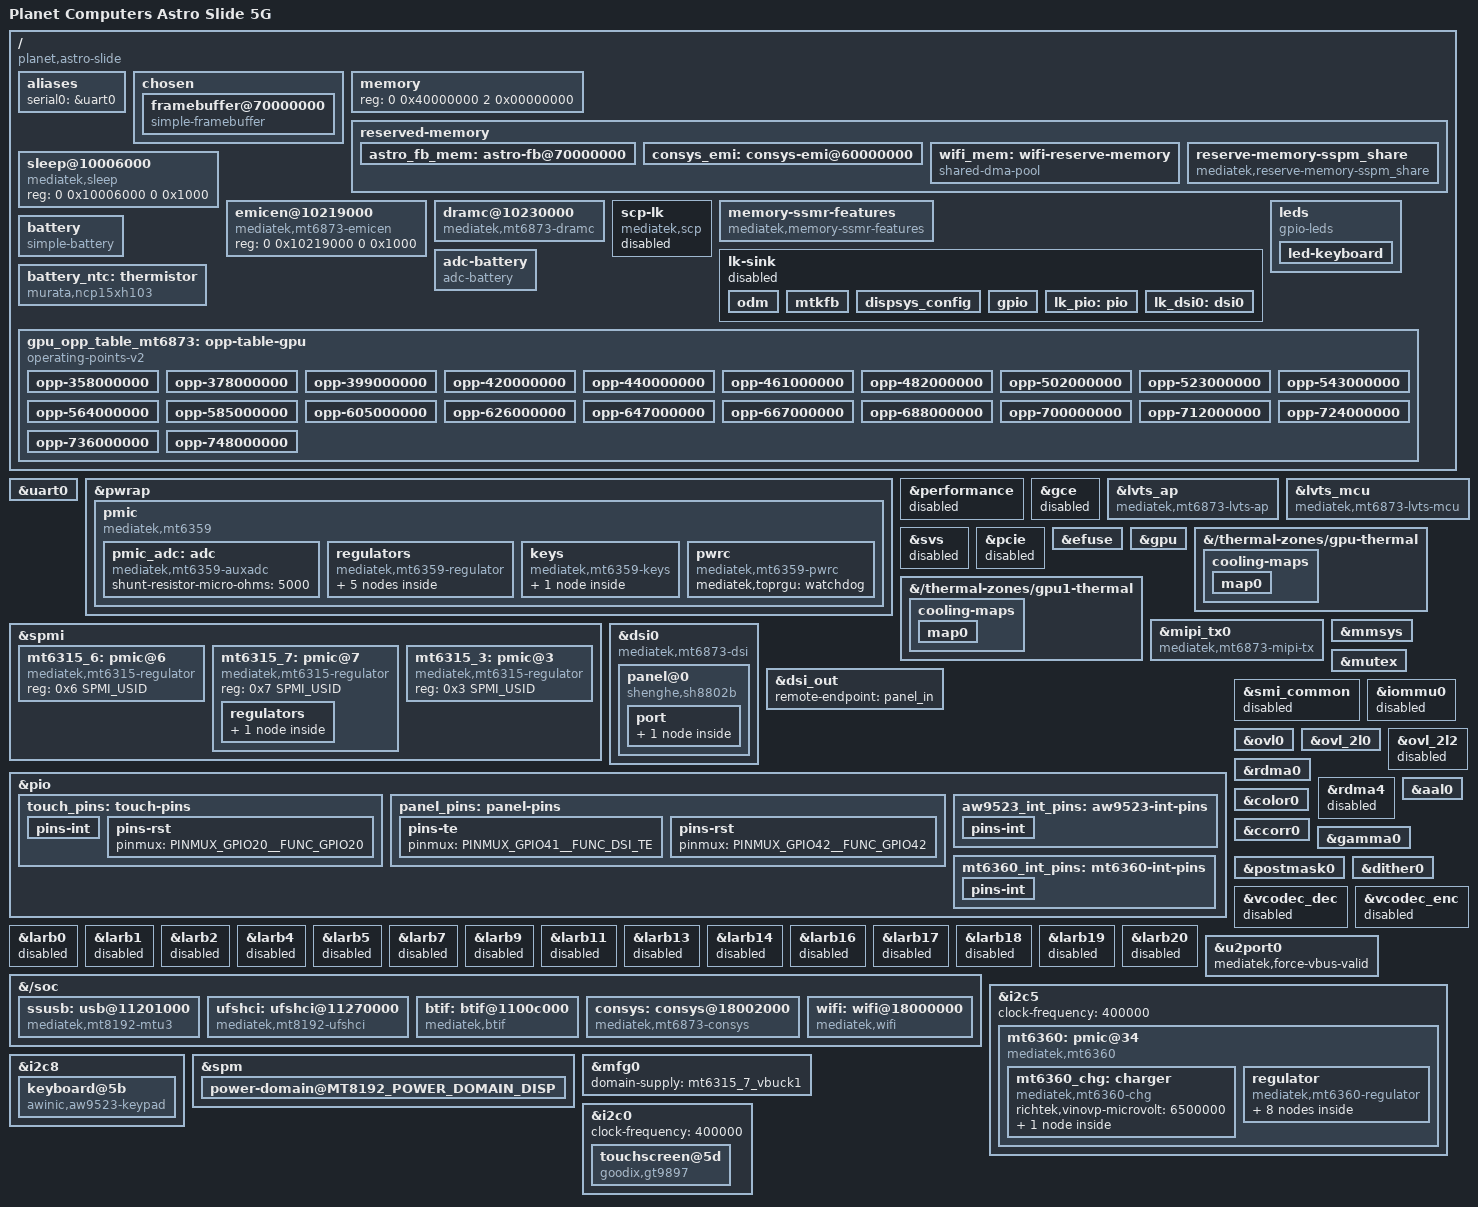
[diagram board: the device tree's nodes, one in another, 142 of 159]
// SPDX-License-Identifier: GPL-2.0-only
/*
 * Planet Computers Astro Slide 5G (MediaTek MT6873 / Dimensity 800)
 *
 * Phase P1 "escape test" skeleton: CPUs, GIC, timers, watchdog, UART0,
 * LK's framebuffer (simpledrm) and the keyboard backlight as a heartbeat.
 * Built on mt8192.dtsi: the MT6873 shares the MT8192 register map (97/102
 * mt8192.dtsi addressed nodes at identical addresses) and pin table (228
 * pins, identical mux functions). Receipts: docs/hardware-map.md.
 *
 * Board facts are from Planet's 4.14.186 BSP (astro-kernel a79860700:
 * arch/arm64/boot/dts/mediatek/mt6873.dts + aeon_gpio.dtsi) and from the
 * stock images dumped 2026-11-25 (docs/p0-findings.md).
 *
 * Deliberately NOT enabled (AGENTS.md rules 3 and 5):
 *  - pwrap / MT6359P / mt6359-keys: nothing in Linux may touch the PMIC
 *    until the power-key reset path is understood (STRUP_CON12 vs the
 *    TOP_RST_MISC register mainline mtk-pmic-keys writes).
 *  - Display pipeline (mmsys, OVL, RDMA, DSI, M4U): LK owns the SH8802B
 *    command-mode panel; Linux only reads its registers (initramfs).
 *  - SPMI/MT6315, SCP, GPU, everything else (USB: device port only;
 *    UFS without its VCC regulator; i2c8 for the keyboard only: below).
 *
 * LK contract (same LK family as the Cosmo, lk_a strings):
 *  - LK applies `dtbo` to this DTB and refuses to boot if that fails:
 *    build with -@ and flash the no-op overlay (dtbo/astro-noop.dts).
 *  - LK needs /chosen/bootargs (bootargs.c fdt_bootargs) and rewrites
 *    the node at the exact path /memory ("ERROR: /memory node not exist,
 *    while(1)").
 *  - LK adds its own mblock-N-<name> no-map carve-outs to /reserved-memory
 *    (ATF, TEE, SSPM, SPM, SCP, modem, framebuffer, ram_console, pstore):
 *    none of them is declared here (a duplicate hung the Gemini), but the
 *    container must exist, with the vendor nodes LK's fixups look up
 *    (below the memory node).
 */

/dts-v1/;
#include <dt-bindings/gpio/gpio.h>
#include <dt-bindings/spmi/spmi.h>
#include <dt-bindings/iio/adc/mediatek,mt6359-auxadc.h>
#include <dt-bindings/input/input.h>
#include <dt-bindings/interrupt-controller/irq.h>
#include <dt-bindings/leds/common.h>
#include <dt-bindings/phy/phy.h>
#include "mt8192.dtsi"

/ {
	model = "Planet Computers Astro Slide 5G";
	chassis-type = "handset";
	compatible = "planet,astro-slide", "mediatek,mt6873",
		     "mediatek,mt8192";

	aliases {
		serial0 = &uart0;
	};

	chosen {
		#address-cells = <2>;
		#size-cells = <2>;
		ranges;

		/* vendor: console=ttyS0,921600n1; no UART pad is known yet */
		stdout-path = "serial0:921600n8";

		/*
		 * LK builds the kernel cmdline on top of this property and
		 * asserts without it (Cosmo LK log 2026-10-25; the Astro LK
		 * carries the same app/mt_boot/bootargs.c fdt_bootargs).
		 * The boot.img header cmdline adds the rest.
		 */
		bootargs = "console=tty0 console=ttyS0,921600n1";

		/*
		 * Console framebuffer: our own buffer (astro_fb_mem below), not
		 * LK's. LK's framebuffer (0x7dd80000, OVL0_2L layer 0) sits in a
		 * mapped mblock (map:1): arm64 refuses ioremap/WC of mapped RAM
		 * (simpledrm -12, usb2 dmesg), and a second reservation over an LK
		 * mblock made the Cosmo's LK refuse to boot. The display path is
		 * pointed at this buffer by /bin/astro-disp fb (OVL0_2L layer 0
		 * address), keeping LK's layer setup: 1080x2340, pitch 4352,
		 * eBGRA8888 (B,G,R,A in memory = a8r8g8b8, Cosmo-proven).
		 * The panel is command mode: nothing appears until astro-disp
		 * sends a frame.
		 */
		framebuffer@70000000 {
			compatible = "simple-framebuffer";
			reg = <0 0x70000000 0 0x9b6400>;
			width = <1080>;
			height = <2340>;
			stride = <4352>;
			format = "a8r8g8b8";
		};
	};

	/*
	 * 8 GiB at 0x40000000: DRAM rank0 0x100000000 + rank1 0x100000000
	 * (preloader log in expdb). Named "memory" (not memory@40000000):
	 * LK looks the node up by that exact path and rewrites it.
	 */
	memory {
		device_type = "memory";
		reg = <0 0x40000000 2 0x00000000>;
	};

	/*
	 * Vendor nodes LK's final fixup pass looks up in this DTB (try1b,
	 * 2026-11-25: each missing one logged an error that a stock boot does
	 * not log, then "ASSERT at (app/mt_boot/mt_boot.c:991)"). Copied from
	 * the stock base DTB (boot_a dtb section) minus phandle references to
	 * vendor nodes we do not carry. No mainline driver matches any of
	 * these compatibles.
	 *
	 * /reserved-memory: LK adds its mblock-N-<name> carve-outs here
	 * ("[DRAMC] Warning: can't find reserved-memory node") and resizes
	 * the SSPM pool by path ("SSPM: no reserved mem found, skip").
	 * Nothing LK reserves itself is declared (Gemini lesson).
	 */
	reserved-memory {
		#address-cells = <2>;
		#size-cells = <2>;
		ranges;

		/*
		 * Console framebuffer (chosen/framebuffer@70000000). Free RAM in
		 * LK's map (its mblock/reserve list, docs/p0-findings.md: nothing
		 * between 0x60000000 and 0x77ff0000). no-map so simpledrm's
		 * ioremap path works and the display engine reads uncached data.
		 */
		astro_fb_mem: astro-fb@70000000 {
			reg = <0 0x70000000 0 0xa00000>;
			no-map;
		};

		/*
		 * Wi-Fi W2: CONSYS EMI window (stock: 4 MiB, 16 MiB aligned,
		 * dynamic in 0x40000000-0xc0000000). Fixed here, in the free
		 * 0x60000000-0x77ff0000 gap of LK's map (p0-findings; checked
		 * again against every mblock LK logged, 2026-11-25), clear of
		 * LK's scratch (0x4e000000-0x56000000) and load areas.
		 */
		consys_emi: consys-emi@60000000 {
			reg = <0 0x60000000 0 0x400000>;
			no-map;
		};

		/* Wi-Fi DMA pool, as stock (gen4m reads "size") */
		wifi_mem: wifi-reserve-memory {
			compatible = "shared-dma-pool";
			no-map;
			size = <0 0x600000>;
			alignment = <0 0x1000000>;
			alloc-ranges = <0 0x40000000 0 0x80000000>;
		};

		reserve-memory-sspm_share {
			compatible = "mediatek,reserve-memory-sspm_share";
			no-map;
			status = "okay";
			size = <0 0x510000>;
			alignment = <0 0x10000>;
			alloc-ranges = <0 0x40000000 0 0x60000000>;
		};
	};

	/* LK records the SPM firmware here ("/sleep not found. LINE: 101") */
	sleep@10006000 {
		compatible = "mediatek,sleep";
		reg = <0 0x10006000 0 0x1000>;
	};

	/* "ERROR: EMI info incorrect" without it */
	emicen@10219000 {
		compatible = "mediatek,mt6873-emicen", "mediatek,common-emicen";
		reg = <0 0x10219000 0 0x1000>;
	};

	/* "[set_fdt_dramc] get_path_offset fail" / "DRAMC info incorrect" */
	dramc@10230000 {
		compatible = "mediatek,mt6873-dramc", "mediatek,common-dramc";
		reg = <0 0x10230000 0 0x2000>, <0 0x10240000 0 0x2000>,
		      <0 0x10234000 0 0x1000>, <0 0x10244000 0 0x1000>,
		      <0 0x10238000 0 0x2000>, <0 0x10248000 0 0x2000>,
		      <0 0x10236000 0 0x1000>, <0 0x10246000 0 0x1000>,
		      <0 0x10006000 0 0x1000>;
		mr4_version = <1>;
		mr4_rg = <0x90 0xffff 0>;
		fmeter_version = <1>;
		crystal_freq = <52>;
		pll_id = <0x50c 0x100 8>;
		shu_lv = <0x50c 0x30000 16>;
		shu_of = <0x700>;
		sdmpcw = <0x704 0xffff0000 16 0x724 0xffff0000 16>;
		prediv = <0x708 0xc0000 18 0x728 0xc0000 18>;
		posdiv = <0x708 7 0 0x728 7 0>;
		ckdiv4 = <0x874 4 2 0x874 4 2>;
		pll_md = <0x744 0x100 8 0x744 0x100 8>;
		cldiv2 = <0x8b4 2 1 0x8b4 2 1>;
		fbksel = <0x70c 0x40 6 0x70c 0x40 6>;
		dqsopen = <0x870 0x100000 20 0x870 0x100000 20>;
		dqopen = <0x870 0x200000 21 0x870 0x200000 21>;
	};

	/*
	 * LK sets the SCP core status here ("[SCP] platform_fdt_scp: getting
	 * node from dtb fails"). Only the properties LK reads; no reg, so it
	 * claims no MMIO. Mainline SCP stays off (CONFIG_MTK_SCP=n).
	 */
	scp-lk {
		compatible = "mediatek,scp";
		status = "disabled";
		core_0 = "enable";
		scp_sramSize = <0x100000>;
	};

	/*
	 * Secure-memory sizes LK's memory_ssmr_fixup reads (stock logs the
	 * scenarios, then "get ssmr-reserved-cma_memory failed" and goes on;
	 * no ssmr/zmc pool is declared, so it fails the same way here).
	 */
	memory-ssmr-features {
		compatible = "mediatek,memory-ssmr-features";
		svp-size = <0 0x10000000>;
		2d_fr-size = <0 0>;
		tui-size = <0 0x4000000>;
		prot-sharedmem-size = <0 0x8000000>;
		ta-elf-size = <0 0x1000000>;
		ta-stack-heap-size = <0 0x6000000>;
		sdsp-tee-sharedmem-size = <0 0x1000000>;
		sdsp-firmware-size = <0 0x1000000>;
	};

	/*
	 * Landing area for LK's second `dtbo` pass (display test 1,
	 * 2026-11-25). LK applies dtbo/astro-lk.dts to its own DTB, where it
	 * feeds LK's panel, backlight and GPIO setup, and then to this DTB,
	 * where a failure stops the boot. Its fragments target odm, pio,
	 * mtkfb, dispsys_config, dsi0 and gpio. Here those symbols all point
	 * into this node: bin/build-boot-img.sh rewrites __symbols__ pio and
	 * dsi0 (mainline labels of the real pinctrl and DSI nodes) to
	 * lk_pio / lk_dsi0. No compatible and disabled, so Linux never
	 * creates a device for anything the overlay puts here.
	 */
	lk-sink {
		status = "disabled";

		odm: odm {
		};

		mtkfb: mtkfb {
		};

		dispsys_config: dispsys_config {
		};

		gpio: gpio {
		};

		lk_pio: pio {
		};

		lk_dsi0: dsi0 {
		};
	};

	/*
	 * Heartbeat on the keyboard backlight, the only light Linux can
	 * drive without the PMIC: GPIO28, active high (vendor aeon_gpio.dtsi
	 * keyboardlight_gpio_low = GPIO28 output-low = off;
	 * aw9523_key.c drives it as PWM0 at 100 % for full on). Blinking =
	 * the kernel is alive; steady/off after a while = it is not.
	 */
	leds {
		compatible = "gpio-leds";

		led-keyboard {
			gpios = <&pio 28 GPIO_ACTIVE_HIGH>;
			function = LED_FUNCTION_KBD_BACKLIGHT;
			color = <LED_COLOR_ID_WHITE>;
			linux,default-trigger = "heartbeat";
			default-state = "off";
		};
	};

	/*
	 * Battery data from the stock DTB (bat_gm30, boot_a dumped
	 * 2026-11-25; identical to the vendor mt6873_battery_table.dtsi):
	 * battery0_profile_t0..t4 (50/25/10/0/-10 C, 100 rows of
	 * {0.1 mAh, 0.1 mV, 0.1 mOhm}) resampled to capacity percent of each
	 * table's own Qmax down to SHUTDOWN_GAUGE0_VOLTAGE 3.40 V; internal
	 * resistance = median of the 25 C resistance column (90 mOhm) +
	 * R_FG_VALUE 5 mOhm + FG_METER_RESISTANCE 10 mOhm, as stock's IR
	 * compensation adds them; temperature scaling = median per table. The charger runs CV 4.35 V (LK's
	 * setting, mt6360-chg); stock battery_cv is 4.40 V.
	 */
	battery: battery {
		compatible = "simple-battery";
		voltage-min-design-microvolt = <3400000>;
		constant-charge-voltage-max-microvolt = <4350000>;
		factory-internal-resistance-micro-ohms = <105000>;
		resistance-temp-table = <50 60>, <25 100>, <10 100>, <0 566>, <(-10) 1024>;
		ocv-capacity-celsius = <25 50 10 0 (-10)>;
		/* 25 C: Qmax 4593.7 mAh to 3.40 V, median R 90 mOhm */
		ocv-capacity-table-0 = <4378700 100>, <4311104 95>, <4245028 90>, <4180598 85>,
					<4118212 80>, <4059719 75>, <4000408 70>, <3955341 65>,
					<3892230 60>, <3850965 55>, <3822506 50>, <3799880 45>,
					<3782051 40>, <3761540 35>, <3738252 30>, <3727280 25>,
					<3698184 20>, <3681272 15>, <3679895 10>, <3670013 5>,
					<3633326 4>, <3589537 3>, <3506523 2>, <3452426 1>,
					<3400000 0>;
		/* 50 C: Qmax 4575.0 mAh to 3.40 V, median R 54 mOhm */
		ocv-capacity-table-1 = <4375000 100>, <4308978 95>, <4244512 90>, <4180937 85>,
					<4119412 80>, <4061913 75>, <4008866 70>, <3961885 65>,
					<3902399 60>, <3857622 55>, <3827781 50>, <3803997 45>,
					<3785460 40>, <3761608 35>, <3731165 30>, <3717634 25>,
					<3708163 20>, <3686832 15>, <3669182 10>, <3653091 5>,
					<3619440 4>, <3569195 3>, <3499717 2>, <3443580 1>,
					<3400000 0>;
		/* 10 C: Qmax 4593.7 mAh to 3.40 V, median R 90 mOhm */
		ocv-capacity-table-2 = <4378700 100>, <4311104 95>, <4245028 90>, <4180598 85>,
					<4118212 80>, <4059719 75>, <4000408 70>, <3955341 65>,
					<3892230 60>, <3850965 55>, <3822506 50>, <3799880 45>,
					<3782051 40>, <3761540 35>, <3738252 30>, <3713958 25>,
					<3693538 20>, <3680753 15>, <3679650 10>, <3670696 5>,
					<3647727 4>, <3602510 3>, <3550219 2>, <3494452 1>,
					<3400000 0>;
		/* 0 C: Qmax 4566.0 mAh to 3.40 V, median R 509 mOhm */
		ocv-capacity-table-3 = <4395400 100>, <4317019 95>, <4250195 90>, <4186618 85>,
					<4126582 80>, <4070805 75>, <3999152 70>, <3940020 65>,
					<3896736 60>, <3857790 55>, <3828199 50>, <3804765 45>,
					<3786148 40>, <3773212 35>, <3770481 30>, <3733814 25>,
					<3694252 20>, <3655631 15>, <3465239 10>, <3444633 5>,
					<3441220 4>, <3437912 3>, <3428367 2>, <3414184 1>,
					<3400000 0>;
		/* -10 C: Qmax 2745.1 mAh to 3.40 V, median R 922 mOhm */
		ocv-capacity-table-4 = <4390100 100>, <4331464 95>, <4284580 90>, <4241603 85>,
					<4200695 80>, <4162661 75>, <4124578 70>, <4086793 65>,
					<4054362 60>, <4006918 55>, <3962901 50>, <3931323 45>,
					<3909276 40>, <3886207 35>, <3863672 30>, <3843448 25>,
					<3825581 20>, <3810172 15>, <3797309 10>, <3786565 5>,
					<3784837 4>, <3781620 3>, <3711396 2>, <3551603 1>,
					<3400000 0>;
	};

	/*
	 * Battery NTC on the MT6359P BAT_TEMP pin. Stock (mtk_battery_table.h,
	 * BAT_NTC_10): 10 kOhm NTC to ground, RBAT_PULL_UP_R 24 kOhm to
	 * RBAT_PULL_UP_VOLT 2.8 V (VBIF28, reads 2.80 V), R = Rpu*V/(Vpu-V);
	 * Fg_Temperature_Table is the NCP15XH103 table value for value.
	 * BIF_NTC_R only applies to BIF batteries (none here).
	 */
	battery_ntc: thermistor {
		compatible = "murata,ncp15xh103";
		io-channels = <&pmic_adc MT6359_AUXADC_BAT_TEMP>;
		pullup-uv = <2800000>;
		pullup-ohm = <24000>;
		pulldown-ohm = <0>;
		#io-channel-cells = <0>;
	};

	/*
	 * Battery voltage and current from the MT6359P AUXADC impedance
	 * measurement (IMP: VBAT and the fuel gauge FG_R_CURR), temperature
	 * from the NTC; capacity by adc-battery-helper (OCV = V - I*R, R
	 * learnt from load steps, OCV table and initial R by temperature).
	 */
	adc-battery {
		compatible = "adc-battery";
		io-channels = <&pmic_adc MT6359_AUXADC_VBAT>,
			      <&pmic_adc MT6359_AUXADC_IBAT>,
			      <&battery_ntc>;
		io-channel-names = "voltage", "current", "temperature";
		monitored-battery = <&battery>;
		power-supplies = <&mt6360_chg>;
	};
};

&uart0 {
	status = "okay";
};

/*
 * pwrap: the only path to the MT6359P (AGENTS.md rule 5, docs/pmic-plan.md).
 * LK/ATF leave it initialised (PMIF INIT_DONE 0x1, WACS2_RDATA bit 15), so
 * mainline skips init; the clock parent is already osc_d10. Step 2 image B:
 * the PMIC core and the power key only; bin/build-boot-img.sh refuses any
 * other shape.
 *
 * MT6359P interrupt: pio EINT 214, level high (stock DTB).
 */
&pwrap {
	status = "okay";

	pmic: pmic {
		compatible = "mediatek,mt6359";
		interrupts-extended = <&pio 214 IRQ_TYPE_LEVEL_HIGH>;
		interrupt-controller;
		#interrupt-cells = <2>;

		/*
		 * Power key (TOPSTATUS bit 1). Reported as Esc, as on the
		 * Cosmo; "hold for power" is userspace policy. The long-press
		 * reset is stated as stock leaves it (STRUP_CON12 0x21e0:
		 * one key, 8 s; hal_kpd.c ONEKEY_REBOOT, LPRST_TD 0), so the
		 * driver (MT6359P delta) finds it set and writes nothing.
		 * No home key on the Astro.
		 */
		/*
		 * AUXADC (step 3A). Probe resets the AUXADC (HK_TOP_RST_CON0
		 * 0xf90 bits 0/3 under the 0xfb4 key); reads write the request
		 * registers (0x1108/0x110a) and IMP0 (0x1208). Nothing in STRUP.
		 * Sense resistor: stock R_FG_VALUE 5 mOhm, CAR_TUNE 100 (1.0).
		 */
		pmic_adc: adc {
			compatible = "mediatek,mt6359-auxadc";
			#io-channel-cells = <1>;
			shunt-resistor-micro-ohms = <5000>;
		};

		/*
		 * Wi-Fi W2 (docs/wifi-stock.md): only the five CONSYS rails, for
		 * the vendor mt6873.c consumer. Every other MT6359P regulator
		 * has no node, so the core gives it no constraints and never
		 * writes it (and regulator_ignore_unused is on the cmdline).
		 * No always-on/boot-on: nothing is enabled at registration.
		 * Ranges cover what LK leaves (VCN33 VOSEL 0xf = 3.5 V, VCN13
		 * 1.3 V, 2026-11-25 read-out) so registration writes nothing;
		 * mt6873.c sets 1.8/1.3/3.3 V itself when Wi-Fi powers on.
		 * Addresses (mainline mt6359p table = Planet registers.h):
		 * VCN18 EN 0x1c2e, VCN13 EN 0x1c1c VOSEL 0x202e, VCN33_1 EN
		 * 0x1be2 b0 / 0x1bf4 b15 VOSEL 0x1f98, VCN33_2 EN 0x1c1a b15
		 * VOSEL 0x1f9c. Nothing near STRUP_CON12 (0xa12).
		 */
		regulators {
			compatible = "mediatek,mt6359-regulator";

			mt6359_vcn18_ldo_reg: ldo_vcn18 {
				regulator-name = "vcn18";
				regulator-min-microvolt = <1800000>;
				regulator-max-microvolt = <1800000>;
			};

			mt6359_vcn13_ldo_reg: ldo_vcn13 {
				regulator-name = "vcn13";
				regulator-min-microvolt = <1300000>;
				regulator-max-microvolt = <1300000>;
			};

			mt6359_vcn33_1_bt_ldo_reg: ldo_vcn33_1_bt {
				regulator-name = "vcn33_1_bt";
				regulator-min-microvolt = <3300000>;
				regulator-max-microvolt = <3500000>;
			};

			mt6359_vcn33_1_wifi_ldo_reg: ldo_vcn33_1_wifi {
				regulator-name = "vcn33_1_wifi";
				regulator-min-microvolt = <3300000>;
				regulator-max-microvolt = <3500000>;
			};

			mt6359_vcn33_2_wifi_ldo_reg: ldo_vcn33_2_wifi {
				regulator-name = "vcn33_2_wifi";
				regulator-min-microvolt = <3300000>;
				regulator-max-microvolt = <3500000>;
			};
		};

		keys {
			compatible = "mediatek,mt6359-keys";
			mediatek,long-press-mode = <1>;
			power-off-time-sec = <8>;

			power {
				linux,keycodes = <KEY_ESC>;
				wakeup-source;
			};
		};

		/*
		 * Power-off (docs/poweroff.md): the vendor MT6873 kernel's
		 * mt6358_power_off() = RG_PWRHOLD (PPCCTL0 0xa08 bit 0) = 0; if
		 * power stays (charger/USB), the vendor "charger" TOPRGU reset
		 * without bypass power key (NONRST_REG2 bit 13 cleared).
		 */
		pwrc {
			compatible = "mediatek,mt6359-pwrc";
			mediatek,toprgu = <&watchdog>;
		};
	};
};

/*
 * First-boot scope (docs/session-log.md 2026-11-25): mt8192.dtsi leaves
 * these enabled, but none is wanted yet. Display, multimedia, IOMMU and
 * GCE belong to LK's display path (panel rule); SPMI is the MT6315 path;
 * performance-controller, SVS and PCIe are MT8192 nodes the
 * vendor MT6873 DT does not have (unverified on this SoC). Clock
 * providers stay: they only register clocks (clk_ignore_unused).
 */
&performance {
	status = "disabled";
};

/*
 * GPU G-S1 (docs/gpu-stock.md): SPMI (mainline spmi-mtk-pmif, AP software
 * channel 2 = the stock AP channel) and the three MT6315 bucks PMICs, for
 * reading only. No regulator constraints on purpose: the regulator core has
 * nothing to apply, so probe only reads; regulator_ignore_unused keeps every
 * rail as the bootloader left it. Stock DT: mt6315@6 vbuck1/3 = CPU
 * (proc1/proc2), mt6315@7 vbuck1 = vgpu, vbuck3/4, mt6315@3 vbuck1/3/4.
 * The SPMI node's assigned parent for pwrap_ulposc_sel (osc_d10) is the
 * live one (CLK_CFG_8 = 0x03010001).
 */
&spmi {
	#address-cells = <2>;
	#size-cells = <0>;
	status = "okay";

	mt6315_6: pmic@6 {
		compatible = "mediatek,mt6315-regulator";
		reg = <0x6 SPMI_USID>;
	};

	mt6315_7: pmic@7 {
		compatible = "mediatek,mt6315-regulator";
		reg = <0x7 SPMI_USID>;

		/*
		 * GPU G-S3: vgpu (stock DT 7_vbuck1). Range = the stock MT6873
		 * OPPs (0.5625-0.69375 V) up to the 0.75 V LK leaves, so the
		 * regulator core writes nothing at registration. Enable ramp
		 * 256 us as the stock DT; 40 us settling covers every stock
		 * DVFS wait (max 36 us). No modes, not always-on.
		 */
		regulators {
			mt6315_7_vbuck1: vbuck1 {
				regulator-name = "Vgpu";
				regulator-min-microvolt = <562500>;
				regulator-max-microvolt = <750000>;
				regulator-enable-ramp-delay = <256>;
				regulator-settling-time-us = <40>;
			};
		};
	};

	mt6315_3: pmic@3 {
		compatible = "mediatek,mt6315-regulator";
		reg = <0x3 SPMI_USID>;
	};
};

&gce {
	status = "disabled";
};

/*
 * Thermal T-S1 (docs/thermal-stock.md): mainline LVTS with the MT6873
 * vendor sequence (lvts_thermal.c delta, compatibles mediatek,mt6873-lvts-*).
 * Same blocks, sensors and efuse calibration as the vendor DT's therm_ctrl;
 * the mt8192.dtsi thermal zones (passive 85 C, critical 100 C) apply.
 */
&lvts_ap {
	compatible = "mediatek,mt6873-lvts-ap";
	status = "okay";
};

&lvts_mcu {
	compatible = "mediatek,mt6873-lvts-mcu";
	status = "okay";
};

&svs {
	status = "disabled";
};

&pcie {
	status = "disabled";
};

/* Read-only (mtk-efuse has no write op): LVTS calibration at 0x1c0. */
&efuse {
	status = "okay";
};

/*
 * GPU G-S3 (docs/gpu-stock.md): Mali-G57 on panfrost with devfreq over the
 * stock MT6873 range (vendor g_opp_table_segment_1, idx 17-38; the MT6873
 * segment starts at idx 17 = 748 MHz). vgpu per OPP; vsram_others stays
 * at 0.75 V (stock: vsram = 0.75 V for every vgpu <= 0.75 V), not
 * described. The MT6873 segment runs 4 shader cores (vendor shader_present
 * 0x50005): mediatek,shader-core-mask (panfrost delta) keeps it so.
 * panfrost is a module, loaded by hand. Cooling device for gpu-thermal.
 */
/delete-node/ &gpu_opp_table;

/ {
	gpu_opp_table_mt6873: opp-table-gpu {
		compatible = "operating-points-v2";

		opp-358000000 { opp-hz = /bits/ 64 <358000000>; opp-microvolt = <562500>; };
		opp-378000000 { opp-hz = /bits/ 64 <378000000>; opp-microvolt = <568750>; };
		opp-399000000 { opp-hz = /bits/ 64 <399000000>; opp-microvolt = <575000>; };
		opp-420000000 { opp-hz = /bits/ 64 <420000000>; opp-microvolt = <581250>; };
		opp-440000000 { opp-hz = /bits/ 64 <440000000>; opp-microvolt = <587500>; };
		opp-461000000 { opp-hz = /bits/ 64 <461000000>; opp-microvolt = <593750>; };
		opp-482000000 { opp-hz = /bits/ 64 <482000000>; opp-microvolt = <600000>; };
		opp-502000000 { opp-hz = /bits/ 64 <502000000>; opp-microvolt = <606250>; };
		opp-523000000 { opp-hz = /bits/ 64 <523000000>; opp-microvolt = <612500>; };
		opp-543000000 { opp-hz = /bits/ 64 <543000000>; opp-microvolt = <618750>; };
		opp-564000000 { opp-hz = /bits/ 64 <564000000>; opp-microvolt = <625000>; };
		opp-585000000 { opp-hz = /bits/ 64 <585000000>; opp-microvolt = <631250>; };
		opp-605000000 { opp-hz = /bits/ 64 <605000000>; opp-microvolt = <637500>; };
		opp-626000000 { opp-hz = /bits/ 64 <626000000>; opp-microvolt = <643750>; };
		opp-647000000 { opp-hz = /bits/ 64 <647000000>; opp-microvolt = <650000>; };
		opp-667000000 { opp-hz = /bits/ 64 <667000000>; opp-microvolt = <656250>; };
		opp-688000000 { opp-hz = /bits/ 64 <688000000>; opp-microvolt = <662500>; };
		opp-700000000 { opp-hz = /bits/ 64 <700000000>; opp-microvolt = <668750>; };
		opp-712000000 { opp-hz = /bits/ 64 <712000000>; opp-microvolt = <675000>; };
		opp-724000000 { opp-hz = /bits/ 64 <724000000>; opp-microvolt = <681250>; };
		opp-736000000 { opp-hz = /bits/ 64 <736000000>; opp-microvolt = <687500>; };
		opp-748000000 { opp-hz = /bits/ 64 <748000000>; opp-microvolt = <693750>; };
	};
};

&gpu {
	operating-points-v2 = <&gpu_opp_table_mt6873>;
	mali-supply = <&mt6315_7_vbuck1>;
	#cooling-cells = <2>;
	mediatek,shader-core-mask = /bits/ 64 <0x50005>;
	status = "okay";
};

&{/thermal-zones/gpu-thermal} {
	cooling-maps {
		map0 {
			trip = <&gpu0_alert>;
			cooling-device = <&gpu THERMAL_NO_LIMIT THERMAL_NO_LIMIT>;
		};
	};
};

&{/thermal-zones/gpu1-thermal} {
	cooling-maps {
		map0 {
			trip = <&gpu1_alert>;
			cooling-device = <&gpu THERMAL_NO_LIMIT THERMAL_NO_LIMIT>;
		};
	};
};

/*
 * Display Stage 3 (docs/display-stock.md): mediatek-drm on the main path
 * OVL0 -> OVL_2L0 -> RDMA0 -> COLOR0 -> CCORR -> AAL0 -> GAMMA -> POSTMASK0
 * -> DITHER0 -> DSI0 -> SH8802B (command mode). No IOMMU yet: the bootloader
 * runs the path with M4U off, so the OVL/RDMA "iommus" are dropped and
 * buffers come from CMA (larbs stay in the bootloader's bypass state).
 * mediatek-drm, the PHY and the panel are modules, not loaded at boot
 * (gemini-debian astro: /etc/modprobe.d blacklist) until the stage is
 * proven. MT6873 compatibles first: stock-Android PHY sequence and D-PHY
 * timing (docs/display-stock.md "Mainline 6.18 gaps").
 */
&mipi_tx0 {
	compatible = "mediatek,mt6873-mipi-tx", "mediatek,mt8183-mipi-tx";
	status = "okay";
};

&dsi0 {
	compatible = "mediatek,mt6873-dsi", "mediatek,mt8183-dsi";
	#address-cells = <1>;
	#size-cells = <0>;
	status = "okay";

	panel@0 {
		compatible = "shenghe,sh8802b";
		reg = <0>;
		pinctrl-names = "default";
		pinctrl-0 = <&panel_pins>;
		/* stock dtbo panel2@0: reset-gpios GPIO42, bias-gpios GPIO87, GPIO88 */
		reset-gpios = <&pio 42 GPIO_ACTIVE_LOW>;
		bias-gpios = <&pio 87 GPIO_ACTIVE_HIGH>, <&pio 88 GPIO_ACTIVE_HIGH>;
		/*
		 * Desktop P1: mounted so that the landscape (keyboard) view is
		 * the panel turned 90 degrees (fbcon=rotate:1 = FB_ROTATE_CW).
		 */
		rotation = <90>;

		port {
			panel_in: endpoint {
				remote-endpoint = <&dsi_out>;
			};
		};
	};
};

&dsi_out {
	remote-endpoint = <&panel_in>;
};

&pio {
	/*
	 * Touch (stock dtbo fragment@35 int_active/reset_active): INT GPIO21
	 * input, RST GPIO20 GPIO (the driver drives it). I2C0 SCL/SDA
	 * GPIO204/205 are in mode 1 from LK (read 2026-11-25).
	 */
	touch_pins: touch-pins {
		pins-int {
			pinmux = <PINMUX_GPIO21__FUNC_GPIO21>;
			input-enable;
		};

		pins-rst {
			pinmux = <PINMUX_GPIO20__FUNC_GPIO20>;
		};
	};

	/* As the bootloader leaves them (stock dtbo lcm_dsi_te, lcm_rst_out*) */
	panel_pins: panel-pins {
		pins-te {
			pinmux = <PINMUX_GPIO41__FUNC_DSI_TE>;
		};

		pins-rst {
			pinmux = <PINMUX_GPIO42__FUNC_GPIO42>;
		};
	};
};

/*
 * Display Stage 2 (docs/display-stock.md): mmsys (clock provider for the
 * DISP domain clocks, reset controller; probe writes nothing) and the
 * display mutex (probe writes nothing) are on. No DRM driver in the kernel,
 * so mmsys's "mediatek-drm" child device stays unbound.
 */
&mmsys {
	status = "okay";
};

&mutex {
	status = "okay";
};

&smi_common {
	status = "disabled";
};

&iommu0 {
	status = "disabled";
};

&ovl0 {
	status = "okay";
	/delete-property/ iommus;
};

&ovl_2l0 {
	status = "okay";
	/delete-property/ iommus;
};

&ovl_2l2 {
	status = "disabled";
};

&rdma0 {
	status = "okay";
	/delete-property/ iommus;
};

&rdma4 {
	status = "disabled";
};

&color0 {
	status = "okay";
};

&ccorr0 {
	status = "okay";
};

&aal0 {
	status = "okay";
};

&gamma0 {
	status = "okay";
};

&postmask0 {
	status = "okay";
};

&dither0 {
	status = "okay";
};

&vcodec_dec {
	status = "disabled";
};

&vcodec_enc {
	status = "disabled";
};

&larb0 {
	status = "disabled";
};

&larb1 {
	status = "disabled";
};

&larb2 {
	status = "disabled";
};

&larb4 {
	status = "disabled";
};

&larb5 {
	status = "disabled";
};

&larb7 {
	status = "disabled";
};

&larb9 {
	status = "disabled";
};

&larb11 {
	status = "disabled";
};

&larb13 {
	status = "disabled";
};

&larb14 {
	status = "disabled";
};

&larb16 {
	status = "disabled";
};

&larb17 {
	status = "disabled";
};

&larb18 {
	status = "disabled";
};

&larb19 {
	status = "disabled";
};

&larb20 {
	status = "disabled";
};

/*
 * Burn-in guard: initramfs/init holds the panel in reset (GPIO42 low via
 * /bin/astro-disp, first thing init does), or with astro.dispkick=1 pushes
 * a black frame through LK's display path instead. It was a gpio-hog here
 * until 2026-11-25; init needs the pin free to keep the panel initialised
 * for display tests. GPIO42 = panel reset (vendor dsi0 panel2 reset-gpios;
 * LK lcm_rst_out states, GPIO mode, output high at handoff).
 */

/*
 * USB device port (right-hand USB-C): the SSUSB controller as mtu3, for a
 * bring-up network (g_ether) and shell. Same IP as the vendor mtu3_0 node
 * (mt6873.dts: mac 0x11201000, ippc 0x11203e00, SPI 96, PHY 0x11e40000)
 * and as mainline's mt8192 xhci node (host-only, left disabled). Mainline
 * mt8192.dtsi has no mtu3 node, so it is added here, shaped like
 * mt8195.dtsi ssusb0.
 *
 * As on the Cosmo (cosmo-linux618 &ssusb): OTG with a role switch that
 * defaults to peripheral, because only the role-switch path forces the
 * IP into device mode (mtu3_dr.c ssusb_set_force_mode); USB 2 only
 * (u3p-dis-msk), else mtu3 waits for a U3 MAC clock that never starts.
 * No host child and no vbus-supply: the host role is never used (dummy
 * regulator). No vusb33-supply either: the PMIC stays out of reach (rule
 * 5); LK/preloader leave the USB rails on (preloader and LK use this port).
 */
&{/soc} {
	ssusb: usb@11201000 {
		compatible = "mediatek,mt8192-mtu3", "mediatek,mtu3";
		reg = <0 0x11201000 0 0x2dff>, <0 0x11203e00 0 0x0100>;
		reg-names = "mac", "ippc";
		interrupts = <GIC_SPI 96 IRQ_TYPE_LEVEL_HIGH 0>;
		phys = <&u2port0 PHY_TYPE_USB2>;
		clocks = <&infracfg CLK_INFRA_SSUSB>,
			 <&apmixedsys CLK_APMIXED_USBPLL>,
			 <&clk26m>,
			 <&clk26m>;
		clock-names = "sys_ck", "ref_ck", "mcu_ck", "dma_ck";
		dr_mode = "otg";
		usb-role-switch;
		role-switch-default-mode = "peripheral";
		maximum-speed = "high-speed";
		mediatek,u3p-dis-msk = <0x1>;
	};
};

/*
 * VBUS is sensed by the charger (MT6360), not by the U2 PHY: without the
 * PHY's VBUSVALID/AVALID/SESSEND inputs forced the UDC stays "not
 * attached" with D+ pulled up (usb1, 2026-11-25). Forcing them (vendor
 * phy-mtk-mt6873.c phy_init_soc values) gave "configured" (usb2,
 * init devmem test). Kernel delta: phy-mtk-tphy.c.
 */
&u2port0 {
	mediatek,force-vbus-valid;
};

/*
 * UFS (stock: 11270000.ufshci, partitions on sdc; docs/p0-findings.md).
 * Mainline mt8192.dtsi has no UFS node (Chromebooks boot eMMC); the IP is
 * MediaTek's legacy UFS host (REG_UFS_MTK_IP_VER 0x20160706, read on the
 * running board 2026-11-25 = mainline IP_LEGACY_VER_MT6893), UFSHCI 2.0,
 * no MCQ (CAP 0x3587071F). Vendor node (mt6873.dts ufshci@11270000): SPI
 * 105, 2 lanes, clocks UFS_CG / UNIPRO_SYSCLK_CG / UFS_MP_SAP_BCLK_CG /
 * AES_UFSFDE_CG, which are mainline mt8192 infracfg INFRA2 bits 28/11/13/29
 * (same bits as the vendor ufs-mtk-platform.h). The vendor driver does no
 * M-PHY setup (ufs_mtk_init_mphy is empty), so no phys here.
 *
 * No vcc-supply: VCC is the MT6359P VEMC LDO and nothing in Linux may
 * reach the PMIC (rule 5). LK/preloader boot from this UFS and leave VCC
 * on; without a regulator the driver can never switch it off. Device
 * reset and ref-clk go through ATF SiP 0x82000276 (mainline cmds 2 and 8
 * = the vendor's MTK_SIP_KERNEL_UFS_CTL calls).
 */
&{/soc} {
	ufshci: ufshci@11270000 {
		compatible = "mediatek,mt8192-ufshci", "mediatek,mt8183-ufshci";
		reg = <0 0x11270000 0 0x2300>;
		interrupts = <GIC_SPI 105 IRQ_TYPE_LEVEL_HIGH 0>;
		clocks = <&infracfg CLK_INFRA_UFS>,
			 <&infracfg CLK_INFRA_UNIPRO_SYS>,
			 <&infracfg CLK_INFRA_UFS_MP_SAP_B>,
			 <&infracfg CLK_INFRA_AES_UFSFDE>;
		clock-names = "ufs", "unipro_sysclk", "unipro_mp_bclk",
			      "ufs_aes";
		freq-table-hz = <0 0>, <0 0>, <0 0>, <0 0>;
		lanes-per-direction = <2>;
		mediatek,ufs-disable-mcq;
	};
};

/*
 * i2c5: MT6360 (PMIC 0x1a, PMU/charger 0x34, TCPC 0x4e, LDO 0x64; stock
 * i2c5 bus scan, docs/p0-findings.md). Single-channel controller (vendor
 * mt6873.dts i2c5: reg size 0x1000, no ch_offset), so mainline's base.
 * SCL5/SDA5 = GPIO202/203 mode 1, already set by LK (GPIO MODE25
 * 0x11111111 on the running board).
 */
&i2c5 {
	clock-frequency = <400000>;
	status = "okay";

	/*
	 * MT6360 sub-PMIC: charger, ADC, regulators (mainline mt6360-core;
	 * the ADC binds by MFD cell name, the binding has no adc child).
	 * IRQB = GPIO24, active low (stock dtbo fragment@21 intr_gpio 24;
	 * vendor mt6360_pmu_irq.c IRQF_TRIGGER_FALLING, as mainline boards).
	 * Not described here, so their drivers stay off: TCPC (Type-C/PD,
	 * later), flash/RGB LEDs.
	 */
	mt6360: pmic@34 {
		compatible = "mediatek,mt6360";
		reg = <0x34>;
		interrupts-extended = <&pio 24 IRQ_TYPE_EDGE_FALLING>;
		interrupt-names = "IRQB";
		interrupt-controller;
		#interrupt-cells = <1>;
		pinctrl-names = "default";
		pinctrl-0 = <&mt6360_int_pins>;
		wakeup-source;

		/*
		 * Input OVP 6.5 V: the value LK leaves in CHG_CTRL19 (0x20,
		 * 2026-11-25) and the driver default; 5 V USB only until PD.
		 */
		mt6360_chg: charger {
			compatible = "mediatek,mt6360-chg";
			richtek,vinovp-microvolt = <6500000>;

			usb-otg-vbus-regulator {
				regulator-name = "mt6360-otg-vbus";
				regulator-min-microvolt = <4425000>;
				regulator-max-microvolt = <5825000>;
			};
		};

		/*
		 * Names and ranges from the vendor mt6360.dtsi. Every range
		 * contains the voltage LK left (read 2026-11-25, session log),
		 * so the regulator core changes nothing at probe, except LDO2
		 * (vtp, touch AVDD): fixed at the stock 2.6 V, set while off. BUCK2, LDO6
		 * and LDO7 feed the DRAM, BUCK1 the APU: always on, as stock.
		 * LDO1/2/3/5 were off at boot and stay so until a consumer
		 * (fingerprint, touch, SD card) claims them.
		 */
		regulator {
			compatible = "mediatek,mt6360-regulator";

			mt6360_buck1: buck1 {
				regulator-name = "vmdla";	/* 1.125 V, on */
				regulator-min-microvolt = <300000>;
				regulator-max-microvolt = <1300000>;
				regulator-always-on;
			};

			mt6360_buck2: buck2 {
				regulator-name = "vdram1";	/* 0.75 V, on */
				regulator-min-microvolt = <300000>;
				regulator-max-microvolt = <1300000>;
				regulator-always-on;
			};

			mt6360_ldo1: ldo1 {
				regulator-name = "vfp";		/* 1.8 V, off */
				regulator-min-microvolt = <1200000>;
				regulator-max-microvolt = <3600000>;
			};

			/*
			 * Touch AVDD (stock vtouch). Boot default 1.8 V, at which
			 * the GT9897 does not answer. Stock: the FocalTech
			 * driver probes first on every boot and requests
			 * 2.6-3.3 V on vtouch (lowest = 2.6 V) before the Goodix
			 * driver enables it; the GT9897 answers at 2.6 V
			 * (docs/touch-stock.md; user choice 2026-11-26). Set by
			 * the regulator core at probe while still off.
			 */
			mt6360_ldo2: ldo2 {
				regulator-name = "vtp";
				regulator-min-microvolt = <2600000>;
				regulator-max-microvolt = <2600000>;
			};

			mt6360_ldo3: ldo3 {
				regulator-name = "vmc";		/* 3.0 V, off */
				regulator-min-microvolt = <1200000>;
				regulator-max-microvolt = <3600000>;
			};

			mt6360_ldo5: ldo5 {
				regulator-name = "vmch";	/* 2.95 V, off */
				regulator-min-microvolt = <2700000>;
				regulator-max-microvolt = <3600000>;
			};

			mt6360_ldo6: ldo6 {
				regulator-name = "vmddr";	/* 0.75 V, on */
				regulator-min-microvolt = <500000>;
				regulator-max-microvolt = <2100000>;
				regulator-always-on;
			};

			mt6360_ldo7: ldo7 {
				regulator-name = "vdram2";	/* 0.6 V, on */
				regulator-min-microvolt = <500000>;
				regulator-max-microvolt = <2100000>;
				regulator-always-on;
			};
		};
	};
};

/*
 * Keyboard AW9523B on i2c8 (stock dtbo fragment@47: aw9523_key@5b, 400 kHz,
 * open drain). SCL8/SDA8 = GPIO122/123 mode 1, already set by LK (GPIO
 * MODE15 0x00111111 on the running board), so no pinctrl for the bus.
 * Also on this bus (stock fragment@29): camera EEPROM 0x51, not described.
 */
&i2c8 {
	/*
	 * Multi-channel I2C (vendor mt6873.dts i2c8: ch_offset_default 0x100,
	 * ch_offset_ccu 0x200; i2c-mtk.c programs transfers at base+0x100).
	 * At base+0 (mainline) CONTROL/TIMING/START writes do not stick and
	 * every transfer times out without an interrupt (ufskbd1,
	 * 2026-11-25); the same mainline driver with its base at +0x100 reads
	 * the AW9523 ID 0x23 with no other change (test module, shadow init
	 * and multi-channel FIFO clear not needed). So the register window
	 * starts at the AP channel; 0xf00 keeps it inside this controller
	 * (mainline mt8192 regs used: up to 0xf8 + MULTI_DMA 0x8c; DCM 0xf88
	 * is not written, dcm = 0). DMA window unchanged.
	 */
	reg = <0 0x11d01100 0 0xf00>,
	      <0 0x10217780 0 0x180>;
	clock-frequency = <400000>;
	mediatek,use-open-drain;
	status = "okay";

	/*
	 * Same matrix as the Cosmo (vendor aw9523_key.c key_map[] identical:
	 * rows P0_0..7, columns P1_0..6), so the Cosmo driver and keymap.
	 * Fn: KEY_LEFTMETA as on the Cosmo (vendor: KEY_FN).
	 * Stock: interrupt EINT2 level-low, GPIO2 pull-up (fragment@53,
	 * aw9523pin); HWEN GPIO5, low = shutdown (aw9523_hwen_low; output
	 * low on the running board before this driver).
	 */
	keyboard@5b {
		compatible = "awinic,aw9523-keypad";
		reg = <0x5b>;
		pinctrl-names = "default";
		pinctrl-0 = <&aw9523_int_pins>;
		interrupts-extended = <&pio 2 IRQ_TYPE_LEVEL_LOW>;
		reset-gpios = <&pio 5 GPIO_ACTIVE_LOW>;
		keypad,num-rows = <8>;
		keypad,num-columns = <7>;
		linux,keymap = <
			/* col 0 (P1_0) */
			MATRIX_KEY(0, 0, KEY_1)
			MATRIX_KEY(1, 0, KEY_U)
			MATRIX_KEY(2, 0, KEY_S)
			MATRIX_KEY(3, 0, KEY_Z)
			MATRIX_KEY(4, 0, KEY_COMMA)
			MATRIX_KEY(5, 0, KEY_APOSTROPHE)
			MATRIX_KEY(6, 0, KEY_8)
			MATRIX_KEY(7, 0, KEY_J)
			/* col 1 (P1_1) */
			MATRIX_KEY(0, 1, KEY_2)
			MATRIX_KEY(1, 1, KEY_W)
			MATRIX_KEY(2, 1, KEY_D)
			MATRIX_KEY(3, 1, KEY_C)
			MATRIX_KEY(4, 1, KEY_LEFTALT)
			MATRIX_KEY(5, 1, KEY_LEFT)
			MATRIX_KEY(6, 1, KEY_9)
			MATRIX_KEY(7, 1, KEY_K)
			/* col 2 (P1_2) */
			MATRIX_KEY(0, 2, KEY_3)
			MATRIX_KEY(1, 2, KEY_Y)
			MATRIX_KEY(2, 2, KEY_TAB)
			MATRIX_KEY(3, 2, KEY_N)
			MATRIX_KEY(4, 2, KEY_M)
			MATRIX_KEY(5, 2, KEY_DOWN)
			MATRIX_KEY(6, 2, KEY_BACKSPACE)
			MATRIX_KEY(7, 2, KEY_I)
			/* col 3 (P1_3) */
			MATRIX_KEY(0, 3, KEY_4)
			MATRIX_KEY(1, 3, KEY_T)
			MATRIX_KEY(2, 3, KEY_F)
			MATRIX_KEY(3, 3, KEY_X)
			MATRIX_KEY(4, 3, KEY_LEFTMETA)	/* Fn (stock KEY_FN), as the Cosmo */
			MATRIX_KEY(5, 3, KEY_RIGHTSHIFT)
			MATRIX_KEY(6, 3, KEY_P)
			/* col 4 (P1_4) */
			MATRIX_KEY(0, 4, KEY_5)
			MATRIX_KEY(1, 4, KEY_E)
			MATRIX_KEY(2, 4, KEY_G)
			MATRIX_KEY(3, 4, KEY_V)
			MATRIX_KEY(4, 4, KEY_SPACE)
			MATRIX_KEY(5, 4, KEY_UP)
			MATRIX_KEY(6, 4, KEY_O)
			/* col 5 (P1_5) */
			MATRIX_KEY(0, 5, KEY_6)
			MATRIX_KEY(1, 5, KEY_Q)
			MATRIX_KEY(2, 5, KEY_A)
			MATRIX_KEY(3, 5, KEY_B)
			MATRIX_KEY(4, 5, KEY_DOT)
			MATRIX_KEY(5, 5, KEY_RIGHT)
			MATRIX_KEY(6, 5, KEY_ENTER)
			/* col 6 (P1_6) */
			MATRIX_KEY(0, 6, KEY_7)
			MATRIX_KEY(1, 6, KEY_R)
			MATRIX_KEY(2, 6, KEY_H)
			MATRIX_KEY(3, 6, KEY_LEFTSHIFT)
			MATRIX_KEY(4, 6, KEY_LEFTCTRL)
			MATRIX_KEY(5, 6, KEY_L)
			MATRIX_KEY(6, 6, KEY_0)
		>;
	};
};

&pio {
	aw9523_int_pins: aw9523-int-pins {
		pins-int {
			pinmux = <PINMUX_GPIO2__FUNC_GPIO2>;
			input-enable;
			bias-pull-up;
		};
	};

	/* Same as LK leaves it (mode 0, input, pull-up; 2026-11-25). */
	mt6360_int_pins: mt6360-int-pins {
		pins-int {
			pinmux = <PINMUX_GPIO24__FUNC_GPIO24>;
			input-enable;
			bias-pull-up;
		};
	};
};

/*
 * Wi-Fi W2: SCPSYS power domains, CONN only. mt8192.dtsi lists AUDIO, CONN,
 * MFG0 (+MFG1-6) and DISP (+IPE/ISP/MDP/VENC/VDEC/CAM...); mtk-pm-domains
 * powers every listed domain on at probe except KEEP_DEFAULT_OFF ones, the
 * reason it was off (astro.config). Only CONN stays: KEEP_DEFAULT_OFF, so
 * nothing is powered at probe. Mainline MT8192 CONN = Planet's MT6873
 * clk-mt6873-pg.c: PWR_CON 0x304, status bit 1 at 0x16c/0x170, bus
 * protect INFRA 0x2a0/0x2a4/0x228 BIT13|18 then BIT14, 0x2a8/0x2ac/0x258
 * BIT10; domain clock infra_pmic_conn (sw_cg_0 bit 3 in both).
 */
&spm {
	/delete-node/ power-domain@MT8192_POWER_DOMAIN_AUDIO;
	/*
	 * GPU G-S2 (docs/gpu-stock.md): MFG0 (+MFG1-6) back. All off at
	 * handover; scpsys powers them on at probe with the stock MT6873 MTCMOS
	 * sequence and bus-protect masks (clk-mt6873-pg.c MFG1_PROT_STEP*; the
	 * vendor "way_en" bits INFRA_MFG_SECURE_CTRL0 0x1800 are already set).
	 * G-S3: MFG0's domain-supply is vgpu, so vgpu goes off after MFG0
	 * (MFG6..MFG0 first) and on before it, the vendor order
	 * (mt_gpufreq_power_control). MFG1 has none: vsram_others stays on.
	 */

	/*
	 * Display Stage 2: DISP back, without its children (IPE, ISP, ISP2,
	 * MDP, VENC, VDEC(+VDEC2), CAM(+RAWA/B/C)): none is KEEP_DEFAULT_OFF,
	 * so each would be powered on at probe. DISP itself is fully on from
	 * LK (Stage 0: 0x350 = 0xD, status bit 20 set): scpsys_power_on only
	 * sets bits already set, clears ISO/CLK_DIS/SRAM_PDN (already clear)
	 * and clears the DISP bus protection, as the vendor MT6873 power-on
	 * does (clk-mt6873-pg.c DIS_PROT_STEP*; same registers and masks).
	 */
	power-domain@MT8192_POWER_DOMAIN_DISP {
		/delete-node/ power-domain@MT8192_POWER_DOMAIN_IPE;
		/delete-node/ power-domain@MT8192_POWER_DOMAIN_ISP;
		/delete-node/ power-domain@MT8192_POWER_DOMAIN_ISP2;
		/delete-node/ power-domain@MT8192_POWER_DOMAIN_MDP;
		/delete-node/ power-domain@MT8192_POWER_DOMAIN_VENC;
		/delete-node/ power-domain@MT8192_POWER_DOMAIN_VDEC;
		/delete-node/ power-domain@MT8192_POWER_DOMAIN_CAM;
	};
};

/*
 * Wi-Fi W2: MT6873 CONSYS (CONNAC2X2, A-die MT6635) for the vendor
 * WMT/BTIF/gen4m modules (drivers/misc/mediatek-connectivity). reg, IRQs
 * and clock gates as the stock DTB (backup/boot_a.dtb.0.dts); vendor clock
 * IDs mapped by name and checked by register/bit: INFRACFG_AO_BTIF_CG 28 =
 * CLK_INFRA_BTIF (0x80 b31), AP_DMA_CG 129 = CLK_INFRA_AP_DMA (0xd0 b31),
 * CCIF4_AP_CG 113 = CLK_INFRA_CCIF4_AP (0xc0 b28). The stock "conn" clock
 * (vendor scpsys SYS_CONN) is the CONN power domain on mainline (mt6873.c's
 * >= 5.4 path uses pm_runtime). No pinctrl: stock consys_default is
 * empty and GPS (LNA pin) is not used.
 */
&{/soc} {
	btif: btif@1100c000 {
		compatible = "mediatek,btif";
		reg = <0 0x1100c000 0 0x1000>,
		      <0 0x10217d80 0 0x80>,
		      <0 0x10217e00 0 0x80>;
		interrupts = <GIC_SPI 158 IRQ_TYPE_LEVEL_HIGH 0>,
			     <GIC_SPI 152 IRQ_TYPE_LEVEL_HIGH 0>,
			     <GIC_SPI 153 IRQ_TYPE_LEVEL_HIGH 0>;
		clocks = <&infracfg CLK_INFRA_BTIF>,
			 <&infracfg CLK_INFRA_AP_DMA>;
		clock-names = "btifc", "apdmac";
	};

	consys: consys@18002000 {
		compatible = "mediatek,mt6873-consys";
		#address-cells = <2>;
		#size-cells = <2>;
		reg = <0 0x18002000 0 0x1000>,
		      <0 0x10007000 0 0x100>,
		      <0 0x10001000 0 0x1000>,
		      <0 0x10006000 0 0x1000>,
		      <0 0x18007000 0 0x1000>,
		      <0 0x180b1000 0 0x1000>,
		      <0 0x180a3000 0 0x1000>,
		      <0 0x180a5000 0 0x800>,
		      <0 0x180c1000 0 0x1000>,
		      <0 0x18004000 0 0x1000>,
		      <0 0x1024c000 0 0x40>,
		      <0 0x10003000 0 0x1000>;
		interrupts = <GIC_SPI 377 IRQ_TYPE_LEVEL_HIGH 0>,
			     <GIC_SPI 79 IRQ_TYPE_LEVEL_HIGH 0>,
			     <GIC_SPI 378 IRQ_TYPE_LEVEL_HIGH 0>;
		power-domains = <&spm MT8192_POWER_DOMAIN_CONN>;
		clocks = <&infracfg CLK_INFRA_CCIF4_AP>;
		clock-names = "ccif";
		memory-region = <&consys_emi>;
		pmic = <&pmic>;
		vcn18-supply = <&mt6359_vcn18_ldo_reg>;
		vcn13-supply = <&mt6359_vcn13_ldo_reg>;
		vcn33_1_bt-supply = <&mt6359_vcn33_1_bt_ldo_reg>;
		vcn33_1_wifi-supply = <&mt6359_vcn33_1_wifi_ldo_reg>;
		vcn33_2_wifi-supply = <&mt6359_vcn33_2_wifi_ldo_reg>;
	};

	wifi: wifi@18000000 {
		compatible = "mediatek,wifi";
		reg = <0 0x18000000 0 0x100000>;
		interrupts = <GIC_SPI 376 IRQ_TYPE_LEVEL_HIGH 0>;
		memory-region = <&wifi_mem>;
	};
};

&mfg0 {
	domain-supply = <&mt6315_7_vbuck1>;
};

/*
 * Touchscreen (docs/touch-stock.md): Goodix GT9897 (Berlin-A, stock log
 * "ic type is BerlinA", pid 9897) on I2C0 0x5d at 400 kHz, as the stock
 * dtbo fragment@34 gt9897@5d: IRQ GPIO21 falling, reset GPIO20, vtouch =
 * MT6360 LDO2 "vtp" at 2.6 V (see the regulator). Firmware is in the
 * chip's flash. 1080 x 2340 panel coordinates; the touch X axis runs
 * opposite to the panel's (user test 2026-11-26, KWin with the panel
 * orientation: top-left landed bottom-left), hence inverted-x; the
 * compositor rotates with the output.
 */
&i2c0 {
	clock-frequency = <400000>;
	status = "okay";

	touchscreen@5d {
		compatible = "goodix,gt9897";
		reg = <0x5d>;
		interrupts-extended = <&pio 21 IRQ_TYPE_EDGE_FALLING>;
		reset-gpios = <&pio 20 GPIO_ACTIVE_LOW>;
		avdd-supply = <&mt6360_ldo2>;
		pinctrl-names = "default";
		pinctrl-0 = <&touch_pins>;
		touchscreen-size-x = <1080>;
		touchscreen-size-y = <2340>;
		touchscreen-inverted-x;
	};
};
